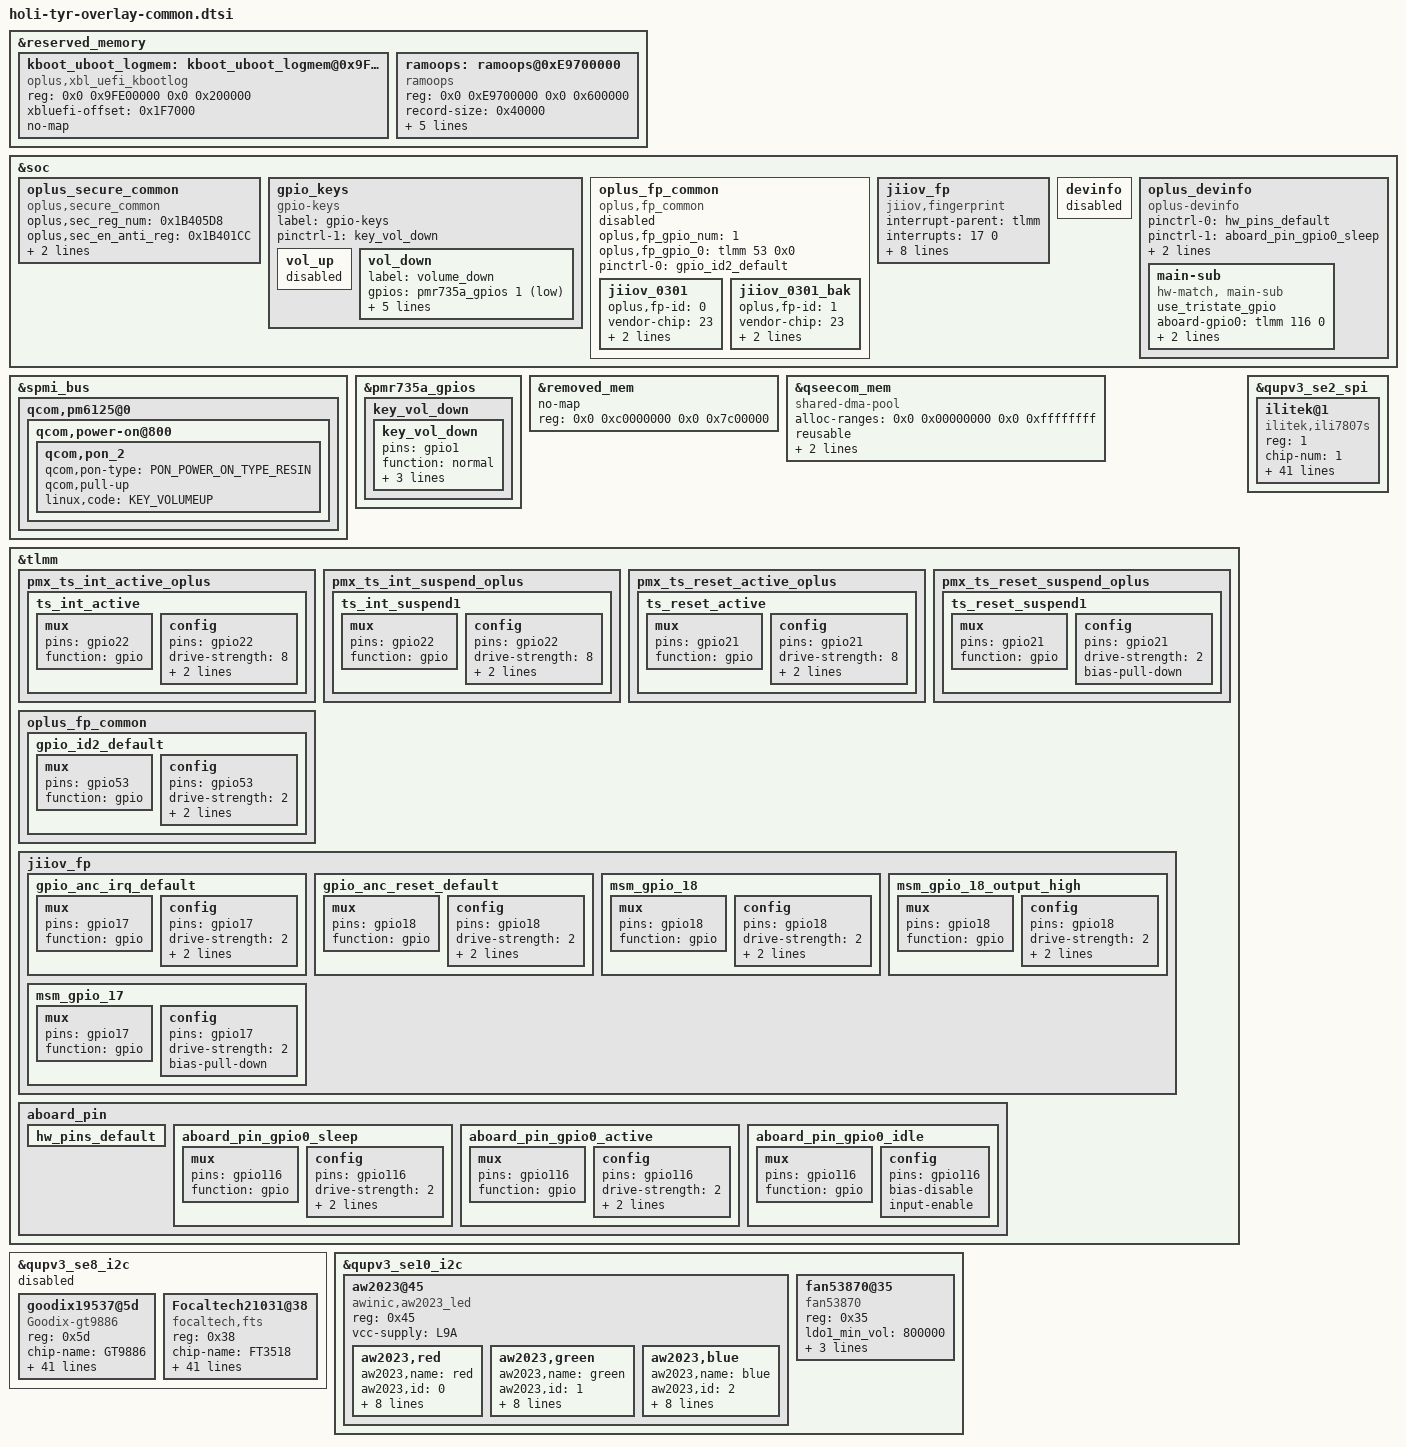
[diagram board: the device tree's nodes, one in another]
#include "../qcom/blair-qrd-nopmi.dtsi"

/* #ifdef OPLUS_ARCH_EXTENDS */
#include "holi-tyr-audio-overlay.dtsi"
/* #endif OPLUS_ARCH_EXTENDS */
/* DTBO: Platform common generic overlay */

&reserved_memory {
	//xbl_uefi_mem address get from: PcdEmbeddedFdBaseAddress +
	//SERIAL_BUFFER_OFFSET = 0x9FC00000 + 0x3F7000 = 0x9FFF7000
	//kernel boot log: 0x9FE00000~ 0x9FFF6FFF, xbl-uefi log: 0x9FFF7000 ~ 0x9FFFFFFF
	kboot_uboot_logmem: kboot_uboot_logmem@0x9FE00000 {
		reg = <0x0 0x9FE00000 0x0 0x200000>;
		compatible = "oplus,xbl_uefi_kbootlog";
		xbluefi-offset = <0x1F7000>;
		no-map;
	};

	//#if IS_ENABLED(CONFIG_OPLUS_FEATURE_DUMP_DEVICE_INFO)
	ramoops: ramoops@0xE9700000 {
		compatible = "ramoops";
		reg = <0x0 0xE9700000 0x0 0x600000>;  //6M
		record-size  = <0x40000>; //256k
		console-size = <0x40000>; //256k
		ftrace-size  = <0x100000>; //1M
		pmsg-size    = <0x100000>; //1M
		devinfo-size = <0x8000>;  //32k
		ecc-size     = <0x0>;
	 };
};

&soc{
	oplus_secure_common {
		compatible = "oplus,secure_common";
		oplus,sec_reg_num = <0x1B405D8>;
		oplus,sec_en_anti_reg = <0x1B401CC>;
		oplus,sec_override1_reg = <0x7860C0>;
		oplus,override1_en_value = <0x1>;
	};
};

&soc {
/*#ifdef OPLUS_FEATURE_TP_BASIC*/
	gpio_keys {
		compatible = "gpio-keys";
		label = "gpio-keys";

		pinctrl-names = "default";
		pinctrl-1 = <&key_vol_down>;
		/* using volume down config update the default value */

		vol_up {
                status="disabled";
		};

		vol_down {
			label = "volume_down";
			gpios = <&pmr735a_gpios 1 GPIO_ACTIVE_LOW>;
			linux,input-type = <1>;
			linux,code = <KEY_VOLUMEDOWN>;
			gpio-key,wakeup;
			debounce-interval = <15>;
			linux,can-disable;
		};
	};
};

&spmi_bus {
	qcom,pm6125@0 {
		qcom,power-on@800 {
/*#ifdef OPLUS_FEATURE_TP_BASIC*/
			qcom,pon_2 {
					qcom,pon-type = <PON_POWER_ON_TYPE_RESIN>;
					qcom,pull-up;
					linux,code = <KEY_VOLUMEUP>;
			};
/*#endif OPLUS_FEATURE_TP_BASIC*/
		};
	};
};

&pmr735a_gpios {
	key_vol_down {
		key_vol_down: key_vol_down {
			pins = "gpio1";
			function = "normal";
			input-enable;
			bias-pull-up;
			power-source = <1>;
		};
	};
};

/* #ifdef OPLUS_FEATURE_CAMERA_COMMON */
//#include "camera/blair-camera-sensor-mtp.dtsi"
/* #endif OPLUS_FEATURE_CAMERA_COMMON */

//#ifdef OPLUS_FEATURE_FINGERPRINT
&soc{
	oplus_fp_common {
		compatible = "oplus,fp_common";
		oplus,fp_gpio_num = <1>;
		oplus,fp_gpio_0 = <&tlmm 53 0x0>;
		pinctrl-names = "default";
		pinctrl-0 = <&gpio_id2_default>;
		status = "disabled";
		jiiov_0301 {
			oplus,fp-id = <0>; /* fp id mapping table */
			vendor-chip = <23>; /* please refer to the struct fp_vendor_t in oplus_fp_commmon.h */
			eng-menu = "-1,-1"; /* represents SNR, inclination test item in engineer menu, and 0/1 means off/on */
			chip-name = "JIIOV_0301";  /* /proc/fp_id, will be displayed in engineer menu  */
		};
		jiiov_0301_bak {
			oplus,fp-id = <1>; /* fp id mapping table */
			vendor-chip = <23>; /* please refer to the struct fp_vendor_t in oplus_fp_commmon.h */
			eng-menu = "-1,-1"; /* represents SNR, inclination test item in engineer menu, and 0/1 means off/on */
			chip-name = "JIIOV_0301";  /* /proc/fp_id, will be displayed in engineer menu  */
		};
	};

	jiiov_fp {
		status = "ok";
		compatible = "jiiov,fingerprint";
		interrupt-parent = <&tlmm>;
		interrupts = <17 0>;
		ldo-supply = <&pm6125_l21>;
		anc,gpio_irq = <&tlmm 17 0x1>;
		anc,gpio_rst = <&tlmm 18 0x0>;
		pinctrl-names = "default", "anc_reset_reset", "anc_reset_active", "anc_irq_active";
		pinctrl-0 = <&gpio_anc_irq_default>, <&gpio_anc_reset_default>;
		pinctrl-1 = <&msm_gpio_18>;
		pinctrl-2 = <&msm_gpio_18_output_high>;
		pinctrl-3 = <&msm_gpio_17>;
	};
};
&removed_mem {
	no-map;
	//reg = <0x0 0xc0000000 0x0 0x5100000>;
	reg = <0x0 0xc0000000 0x0 0x7c00000>;
};

&qseecom_mem {
	compatible = "shared-dma-pool";
	alloc-ranges = <0x0 0x00000000 0x0 0xffffffff>;
	reusable;
	alignment = <0x0 0x400000>;
	//size = <0x0 0x1400000>;
	size = <0x0 0x5000000>;
};
//#endif /*OPLUS_FEATURE_FINGERPRINT*

//#ifdef OPLUS_FEATURE_TP_BASIC
&soc {
	devinfo {
		status = "disabled";
	};
	oplus_devinfo {
		compatible = "oplus-devinfo";

		pinctrl-names = "default", "sleep", "active", "idle";
		pinctrl-0 = <&hw_pins_default>;
		pinctrl-1 = <&aboard_pin_gpio0_sleep>;
		pinctrl-2 = <&aboard_pin_gpio0_active>;
		pinctrl-3 = <&aboard_pin_gpio0_idle>;
		main-sub {
			use_tristate_gpio;
			compatible = "hw-match, main-sub";
			aboard-gpio0 = <&tlmm 116 0>;
			aboard-patterns = <2 2 1 0>;	/*0[high-resistance] 1[pull-down] 2[pull-up]*/
			/*main board*/
			match-projects = <21095 21295 20826 21296>;
		};
	};
};

&tlmm {
	/* add pingrp for touchscreen */
	pmx_ts_int_active_oplus {
		ts_int_active: ts_int_active {
			mux {
				pins = "gpio22";
				function = "gpio";
			};

			config {
				pins = "gpio22";
				drive-strength = <8>;
				bias-disable;
				input-enable;
			};
		};
	};

	pmx_ts_int_suspend_oplus {
		ts_int_suspend1: ts_int_suspend1 {
			mux {
				pins = "gpio22";
				function = "gpio";
			};

			config {
				pins = "gpio22";
				drive-strength = <8>;
				//bias-pull-down;
				bias-pull-up;
				input-enable;
			};
		};
	};

	pmx_ts_reset_active_oplus {
		ts_reset_active: ts_reset_active {
			mux {
				pins = "gpio21";
				function = "gpio";
			};

			config {
				pins = "gpio21";
				drive-strength = <8>;
				output-low;
				bias-disable;
			};
		};
	};

	pmx_ts_reset_suspend_oplus {
		ts_reset_suspend1: ts_reset_suspend1 {
			mux {
				pins = "gpio21";
				function = "gpio";
			};

			config {
				pins = "gpio21";
				drive-strength = <2>;
				bias-pull-down;
			};
		};
	};

	//#ifdef OPLUS_FEATURE_FINGERPRINT
	oplus_fp_common{
		gpio_id2_default: gpio_id2_default {
			mux {
				pins = "gpio53";
				function = "gpio";
			};
			config {
				pins = "gpio53";
				drive-strength = <2>;
				bias-pull-up;
				input-enable;
			};
		};
	};

	jiiov_fp{
		gpio_anc_irq_default: gpio_anc_irq_default {
			mux {
				pins = "gpio17";
				function = "gpio";
			};
			config {
				pins = "gpio17";
				drive-strength = <2>;
				bias-pull-down;
				input-enable;
			};
		};
		gpio_anc_reset_default: gpio_anc_reset_default {
			mux {
				pins = "gpio18";
				function = "gpio";
			};
			config {
				pins = "gpio18";
				drive-strength = <2>;
				bias-disable;
				output-low;
			};
		};

		msm_gpio_18: msm_gpio_18 {
			mux {
				pins = "gpio18";
				function = "gpio";
			};

			config {
				pins = "gpio18";
				drive-strength = <2>;
				bias-disable;
				output-low;
			};
		};

		msm_gpio_18_output_high: msm_gpio_18_output_high {
			mux {
				pins = "gpio18";
				function = "gpio";
			};

			config {
				pins = "gpio18";
				drive-strength = <2>;
				bias-disable;
				output-high;
			};
		};

		msm_gpio_17: msm_gpio_17 {
			mux {
				pins = "gpio17";
				function = "gpio";
			};

			config {
				pins = "gpio17";
				drive-strength = <2>;
				bias-pull-down;
			};
		};
	};
	//#endif /*OPLUS_FEATURE_FINGERPRINT*

	//#ifdef OPLUS_FEATURE_TP_BASIC
        aboard_pin {
		hw_pins_default:hw_pins_default {
		};

		aboard_pin_gpio0_sleep:aboard_pin_gpio0_sleep {
			mux {
				pins = "gpio116";
				function = "gpio";
			};
			config {
				pins = "gpio116";
				drive-strength = <2>;
				bias-pull-down;
				input-enable;
			};
		};

		aboard_pin_gpio0_active:aboard_pin_gpio0_active {
			mux {
				pins = "gpio116";
				function = "gpio";
			};
			config {
				pins = "gpio116";
				drive-strength = <2>;
				bias-pull-up;
				input-enable;
			};
		};

		aboard_pin_gpio0_idle:aboard_pin_gpio0_idle {
			mux {
				pins = "gpio116";
				function = "gpio";
			};
			config {
				pins = "gpio116";
				bias-disable;
				input-enable;
			};
		};
	};
	//#endif /*OPLUS_FEATURE_TP_BASIC*/
};

#include "tyr-21707-tp.dtsi"
&qupv3_se2_spi {
       status = "ok";
       ilitek@1 {
                compatible = "ilitek,ili7807s";
                reg = <1>;
                chip-num = <1>;
                chip-name = "NF_ILI7807S";
                status = "ok";

                spi-max-frequency = <15000000>;    //4800000,9600000,15000000,19200000
                reset-gpio = <&tlmm 21 0x00>;
                interrupt-parent = <&tlmm>;
                interrupts = <22 0x0>;
                irq-gpio = <&tlmm 22 0x2002>;
                cs-gpio = <&tlmm 57 0x00>;

                panel_type = <9>;
                project_id = <21707>;
                touchpanel,max-num-support = <10>;
                touchpanel,tx-rx-num = <16 36>;
                touchpanel,panel-coords = <1080 2412>;
                touchpanel,display-coords = <1080 2412>;
                touchpanel,touchmajor-limit = <0 54>;
                touchpanel,button-type = <4>;
                touchpanel.button-TRx = <0 0>;
                tp_type = <9>;
                platform_support_project = <21707>;
                platform_support_project_dir = <21707>;
                firmware_name = "AB258_DS_ILI001";
                platform_support_project_commandline = "default_commandline";
                pinctrl-names = "default", "pin_set_low", "pin_set_high";
                pinctrl-0 = <&ts_int_active>;
                /*pinctrl-1 = <&ts_int_suspend &ts_reset_suspend>;*/
                pinctrl-1 = <&ts_reset_suspend1>;
                pinctrl-2 = <&ts_reset_active>;

                incell_screen;
                fw_edge_limit_support;
                black_gesture_support;
                charger_pump_support;
                headset_pump_support;
                esd_handle_support;
                //spurious_fingerprint_support;
                //lcd_trigger_fp_check;
                black_gesture_test_support;
                noflash_support;
                smart_gesture_support;
                fw_update_app_support;
                game_switch_support;
                pressure_report_support;
                new_set_irq_wake_support;
                lcd_trigger_load_tp_fw_support;
                fw_update_in_probe_with_headfile;
                health_monitor_support;
        };
};



&qupv3_se8_i2c {
	#address-cells = <1>;
	#size-cells = <0>;

	status = "disabled";

	goodix19537@5d {
		compatible = "Goodix-gt9886";
		reg = <0x5d>;
		chip-name = "GT9886";

		/* Interrupt && Irq-gpio */
		interrupt-parent = <&tlmm>;
		interrupts = <22 0x2002>;

		/* Power Config */
		enable2v8_gpio = <&tlmm 102 0x1>;
		vcc_1v8-supply = <&L13A>;
		vdd_2v8_volt = <3008000>;

		/* Interrupt && Irq-gpio */
		irq-gpio = <&tlmm 22 0x2002>;
		reset-gpio = <&tlmm 21 0x1>;
		pinctrl-names = "default";
		pinctrl-0 = <&ts_int_active &ts_reset_active>;

		touchpanel,max-num-support = <10>;
		touchpanel,tx-rx-num = <15 34>;
		touchpanel,panel-coords = <1080 2400>;
		touchpanel,display-coords = <1080 2400>;
		touchpanel,touchmajor-limit = <0 54>;
		touchpanel,smooth-level = <255 2 15 25 45 60>;
		touchpanel,sensitive-level = <255 20 14 10 6 0>;

		vid_len = <2>;
		project_id = <21095>;
		panel_type = <8>;
		tp_type = <8>;
		firmware_name = "0xAA30800";
		platform_support_project = <21095 21295 21296 20826>;
		platform_support_project_dir = <21095 21095 21095 21095>;
		platform_support_project_commandline = "default_commandline","default_commandline","default_commandline","default_commandline";

		/* SW Support Feature Control */
		register-is-16bit;
		black_gesture_support;
		fw_edge_limit_support;
		pressure_report_support;
		charger_pump_support;
		game_switch_support;
		smart_gesture_support;
		fw_update_app_support;
		fingerprint_underscreen_support;
		esd_handle_support;
		goodix_detail_debug_info_support;
		health_monitor_v2_support;
		/*
		 *Virtual Key Config:
		 *1:touchpanel,button-type: <virtualkey_type  supportted_button-map>
		 *virtualkey_type:
		 *Type 1: using board_properties
		 *Type 2: using same IC (button zone&& touch zone are seprate)
		 *Type 3: using diffrent IC (button zone&& touch zone are seprate)
		 *Type 4: No need of virtual key process
		 *supportted_button-map:select|menu|home|back
		 *
		 *2:touchpanel,button-map
		 *type (X1,Y1)(X2,Y2)(X3,Y3)(Width_X,Hight_Y)--Only when button-type is 0
		 */
		touchpanel,button-type = <4>;
		touchpanel.button-TRx = <0 0>;
	};

	Focaltech21031@38 {
		compatible = "focaltech,fts";
		reg = <0x38>;
		chip-name = "FT3518";

		/* Interrupt && Irq-gpio */
		interrupt-parent = <&tlmm>;
		interrupts = <22 0x2002>;

		/* Power Config */
		enable2v8_gpio = <&tlmm 102 0x1>;
		vcc_1v8-supply = <&L13A>;
		vdd_2v8_volt = <3008000>;

		/* Interrupt && Irq-gpio */
                /* Other HW Resource */
		irq-gpio = <&tlmm 22 0x2002>;
		reset-gpio = <&tlmm 21 0x1>;
		pinctrl-names = "default";
		pinctrl-0 = <&ts_int_active &ts_reset_active>;

		touchpanel,max-num-support = <10>;
		touchpanel,tx-rx-num = <16 34>;
		touchpanel,panel-coords = <1080 2400>;
		touchpanel,display-coords = <1080 2400>;
		touchpanel,touchmajor-limit = <0 54>;
		touchpanel,smooth-level = <255 2 15 25 45 60>;
		touchpanel,sensitive-level = <255 20 14 10 6 0>;
		project_id = <21095>;
		panel_type = <8>;
		tp_type = <8>;
		firmware_name = "0xAA30800";
		platform_support_project = <21095 21295 21296 20826>;
		platform_support_project_dir = <21095 21095 21095 21095>;
		platform_support_project_commandline = "mdss_dsi_oplus21221samsung_ams643ye01_1080_2400_cmd","mdss_dsi_oplus21221samsung_ams643ye01_1080_2400_cmd","mdss_dsi_oplus21221samsung_ams643ye01_1080_2400_cmd","mdss_dsi_oplus21221samsung_ams643ye01_1080_2400_cmd";
		/* SW Support Feature Control */
		black_gesture_support;
		fw_edge_limit_support;
		pressure_report_support;
		charger_pump_support;
		game_switch_support;
		smart_gesture_support;
		fw_update_app_support;
		fingerprint_underscreen_support;
		headset_pump_support;
		//esd_handle_support;
		new_set_irq_wake_support;
		irq_need_dev_resume_ok;
		/*
		*Virtual Key Config:
		*1:touchpanel,button-type: <virtualkey_type  supportted_button-map>
		*virtualkey_type:
		*Type 1: using board_properties
		*Type 2: using same IC (button zone&& touch zone are seprate)
		*Type 3: using diffrent IC (button zone&& touch zone are seprate)
		*Type 4: No need of virtual key process
		*supportted_button-map:select|menu|home|back
		*
		*2:touchpanel,button-map
		*type (X1,Y1)(X2,Y2)(X3,Y3)(Width_X,Hight_Y)--Only when button-type is 0
		*/
		touchpanel,button-type = <4>;
		touchpanel.button-TRx = <0 0>;
	};
};

&qupv3_se10_i2c {
	#address-cells = <1>;
	#size-cells = <0>;

	status = "ok";
	aw2023@45 {
		compatible = "awinic,aw2023_led";
		reg = <0x45>;
		vcc-supply = <&L9A>;

		aw2023,red {
			aw2023,name = "red";
			aw2023,id = <0>;
			aw2023,imax = <2>;
			aw2023,led_default_trigger = "cc_mode";
			aw2023,led-current = <3>;
			aw2023,max-brightness = <255>;
			aw2023,rise-time-ms = <6>;
			aw2023,hold-time-ms = <0>;
			aw2023,fall-time-ms = <6>;
			aw2023,off-time-ms = <4>;
		};

		aw2023,green {
			aw2023,name = "green";
			aw2023,id = <1>;
			aw2023,imax = <2>;
			aw2023,led_default_trigger = "cc_mode";
			aw2023,led-current = <3>;
			aw2023,max-brightness = <255>;
			aw2023,rise-time-ms = <6>;
			aw2023,hold-time-ms = <0>;
			aw2023,fall-time-ms = <6>;
			aw2023,off-time-ms = <4>;
		};

		aw2023,blue {
			aw2023,name = "blue";
			aw2023,id = <2>;
			aw2023,imax = <2>;
			aw2023,led_default_trigger = "cc_mode";
			aw2023,led-current = <3>;
			aw2023,max-brightness = <255>;
			aw2023,rise-time-ms = <6>;
			aw2023,hold-time-ms = <0>;
			aw2023,fall-time-ms = <6>;
			aw2023,off-time-ms = <4>;
		};
	};

	fan53870@35 {
		compatible = "fan53870";
		reg = <0x35>;
		ldo1_min_vol = <800000>;  /*uV*/
		ldo1_max_vol = <1504000>;
		ldo1_step_vol = <8000>;
		pinctrl-names = "default";
		pinctrl-0 = <&pm8008_active>;
	};
};

//#ifdef OPLUS_FEATURE_CHG_BASIC
#include "charge/oplus_charge_holi.dtsi"
//#endif
